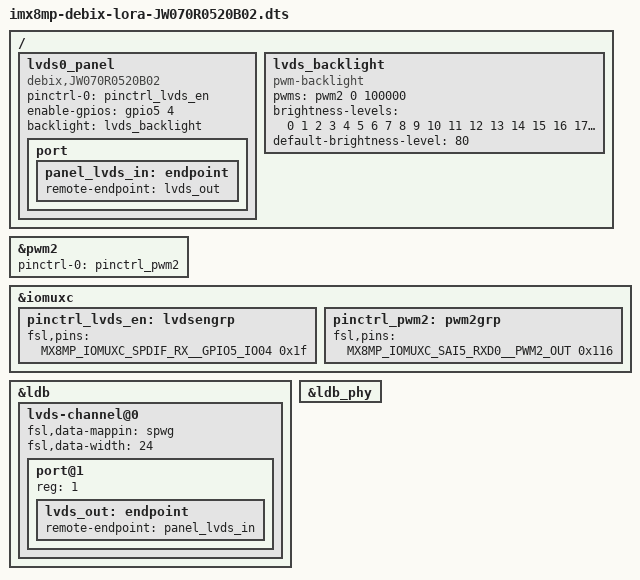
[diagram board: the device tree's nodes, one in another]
// SPDX-License-Identifier: GPL-2.0+
/*
 * Copyright 2020 NXP
 */

#include "imx8mp-debix-lora-board.dts"

/ {
	lvds0_panel {
		compatible = "debix,JW070R0520B02";
		pinctrl-names = "default";
		pinctrl-0 = <&pinctrl_lvds_en>;
		enable-gpios = <&gpio5 4 GPIO_ACTIVE_HIGH>;
		
		backlight = <&lvds_backlight>;

		port {
			panel_lvds_in: endpoint {
				remote-endpoint = <&lvds_out>;
			};
		};
	};
	lvds_backlight: lvds_backlight {
		compatible = "pwm-backlight";
		pwms = <&pwm2 0 100000>;
		status = "okay";
		//pinctrl-0 = <&pinctrl_pwm_en>;
		//enable-gpios = <&gpio5 4 GPIO_ACTIVE_HIGH>;

		brightness-levels = < 0  1  2  3  4  5  6  7  8  9
				     10 11 12 13 14 15 16 17 18 19
				     20 21 22 23 24 25 26 27 28 29
				     30 31 32 33 34 35 36 37 38 39
				     40 41 42 43 44 45 46 47 48 49
				     50 51 52 53 54 55 56 57 58 59
				     60 61 62 63 64 65 66 67 68 69
				     70 71 72 73 74 75 76 77 78 79
				     80 81 82 83 84 85 86 87 88 89
				     90 91 92 93 94 95 96 97 98 99
				    100>;
		default-brightness-level = <80>;
	};


};

&pwm2 {
	pinctrl-names = "default";
	pinctrl-0 = <&pinctrl_pwm2>;
	status = "okay";
};

&iomuxc {
	pinctrl_lvds_en: lvdsengrp {
//		fsl,pins = <
//			MX8MP_IOMUXC_SPDIF_TX__GPIO5_IO03     0x1f
	//	>;
	//};
	//pinctrl_pwm_en: pwmengrp {
		fsl,pins = <
			MX8MP_IOMUXC_SPDIF_RX__GPIO5_IO04     0x1f
		>;
	};

	pinctrl_pwm2: pwm2grp {
		fsl,pins = <
			MX8MP_IOMUXC_SAI5_RXD0__PWM2_OUT 0x116
		>;
	};


};

///delete-node/ &lvds_bridge;

&ldb {
	status = "okay";

	lvds-channel@0 {
		//fsl,data-mapping = "jeida";
                fsl,data-mappin  = "spwg";
		//fsl,data-width = <18>;
		fsl,data-width = <24>;
		status = "okay";

		/delete-node/ port@1;

		port@1 {
			reg = <1>;

			lvds_out: endpoint {
				remote-endpoint = <&panel_lvds_in>;
			};
		};
	};
};

&ldb_phy {
	status = "okay"; 
};
